VERSION ""

NS_ :

BS_:

BU_: Reserve2 SS_WaterTemperature4 SS_WaterTemperature3 SS_WaterTemperature2 SS_WaterTemperature1 SS_WaterPump2 SS_WaterPump1 SS_WaterFlow SS_SteeringAngle SS_RTDS SS_DFR SS_DFL SS_DBR SS_DBL VCU User Reserve1 Telemetry SS_BreakLight SmartSensor PedalIntegratedCircuit Distri Dashboard AclrGPS
VAL_TABLE_ AliveSignal 1 "ONLINE" 0 "OFFLINE" ;

BO_ 563 msg_VCU_cmd_PICoptions: 1 VCU
 SG_ sig_VCU_cmdPICverbose : 0|1@1- (1,0) [0|0] ""  PedalIntegratedCircuit

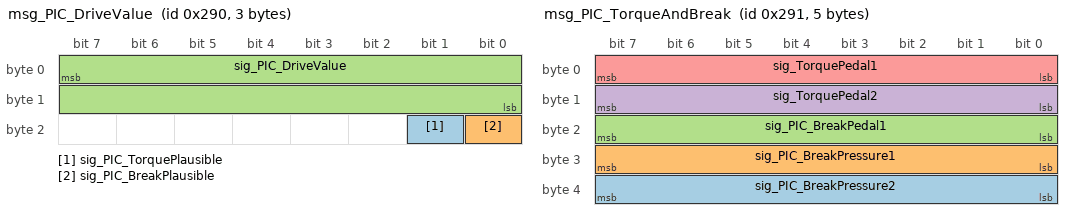
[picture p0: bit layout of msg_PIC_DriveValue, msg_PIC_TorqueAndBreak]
BO_ 656 msg_PIC_DriveValue: 3 PedalIntegratedCircuit
 SG_ sig_PIC_TorquePlausible : 17|1@0+ (1,0) [0|1] "" Vector__XXX
 SG_ sig_PIC_BreakPlausible : 16|1@0+ (1,0) [0|0] ""  VCU
 SG_ sig_PIC_DriveValue : 7|16@0- (0.0030518,0) [-100.0013824|99.9983306] ""  VCU

BO_ 863 msg_SS_WaterFlow1: 1 SS_WaterFlow
 SG_ sig_WaterFlow1 : 7|8@0+ (1,0) [0|255] ""  VCU

BO_ 561 msg_VCU_Alive: 1 VCU
 SG_ sig_VCU_Alive_Signal : 0|1@0+ (1,0) [0|0] ""  User

BO_ 657 msg_PIC_TorqueAndBreak: 5 PedalIntegratedCircuit
 SG_ sig_PIC_BreakPressure2 : 39|8@0+ (1,0) [0|255] ""  VCU
 SG_ sig_PIC_BreakPressure1 : 31|8@0+ (1,0) [0|255] ""  VCU
 SG_ sig_PIC_BreakPedal1 : 23|8@0+ (1,0) [0|255] ""  VCU
 SG_ sig_TorquePedal2 : 15|8@0+ (1,0) [0|255] ""  VCU
 SG_ sig_TorquePedal1 : 7|8@0+ (1,0) [0|255] ""  VCU

BO_ 800 msg_SS_CMD_BrakeLight: 1 VCU
 SG_ sig_BrakeLight_ON : 0|1@0+ (1,0) [0|0] ""  SS_BreakLight

BO_ 801 msg_SS_CMD_RTDS: 1 VCU
 SG_ sig_RTDS_ON : 0|1@0+ (1,0) [0|0] ""  SS_RTDS

BO_ 802 msg_SS_CMD_WaterPump1: 1 VCU
 SG_ sig_WaterPump1_ON : 0|1@0+ (1,0) [0|0] ""  SS_WaterPump1

BO_ 803 msg_SS_CMD_WaterPump2: 1 VCU
 SG_ sig_WaterPump2_ON : 0|1@0+ (1,0) [0|0] ""  SS_WaterPump2

BO_ 848 msg_SS_Deflection_FL: 2 SS_DFL
 SG_ sig_DeflectionFrontLeft : 7|16@0- (1,0) [-32768|32767] ""  VCU

BO_ 849 msg_SS_Deflection_FR: 2 SS_DFR
 SG_ sig_DeflectionFrontRight : 7|16@0- (1,0) [-32768|32767] ""  VCU

BO_ 850 msg_SS_Deflection_BL: 2 SS_DBL
 SG_ sig_DeflectionBackLeft : 7|16@0- (1,0) [-32768|32767] ""  VCU

BO_ 851 msg_SS_Deflection_BR: 2 SS_DBR
 SG_ sig_DeflectionBackRight : 7|16@0- (1,0) [-32768|32767] ""  VCU

BO_ 852 msg_SS_SteeringAngle: 2 SS_SteeringAngle
 SG_ sig_SteeringAngle : 0|16@1- (1,0) [-32768|32767] ""  VCU

BO_ 864 msg_SS_WaterTemp1: 1 SS_WaterTemperature1
 SG_ sig_TemperatureWater1 : 7|8@0+ (1,0) [0|255] ""  VCU

BO_ 865 msg_SS_WaterTemp2: 1 SS_WaterTemperature2
 SG_ sig_TemperatureWater2 : 7|8@0+ (1,0) [0|255] ""  VCU

BO_ 866 msg_SS_WaterTemp3: 1 SS_WaterTemperature3
 SG_ sig_TemperatureWater3 : 7|8@0+ (1,0) [0|255] ""  VCU

BO_ 867 msg_SS_WaterTemp4: 1 SS_WaterTemperature4
 SG_ sig_TemperatureWater4 : 7|8@0+ (1,0) [0|255] ""  VCU

BO_ 868 msg_SS_WaterPump1: 1 SS_WaterPump1
 SG_ sig_WaterPump1_State : 0|1@0+ (1,0) [0|0] ""  VCU

BO_ 869 msg_SS_WaterPump2: 1 SS_WaterPump2
 SG_ sig_WaterPump2_State : 0|1@0+ (1,0) [0|0] ""  VCU

CM_ BU_ SS_WaterTemperature4 "SmartSensor Water Temperature 4";
CM_ BU_ SS_WaterTemperature3 "SmartSensor Water Temperature 3";
CM_ BU_ SS_WaterTemperature2 "SmartSensor Water Temperature 2";
CM_ BU_ SS_WaterTemperature1 "SmartSensor Water Temperature 1";
CM_ BU_ SS_WaterPump2 "SmartSensor Water Pump 2";
CM_ BU_ SS_WaterPump1 "SmartSensor Water Pump 1";
CM_ BU_ SS_WaterFlow "SmartSensor Water Flow";
CM_ BU_ SS_SteeringAngle "SmartSensor steering angle";
CM_ BU_ SS_RTDS "SmartSensor ready to drive sound";
CM_ BU_ SS_DFR "SmartSensor Deflection Front Right";
CM_ BU_ SS_DFL "SmartSensor Deflection Front Left";
CM_ BU_ SS_DBR "Smart Sensor Deflection Back Right";
CM_ BU_ SS_DBL "SmartSensor Deflection Back Left";
CM_ BU_ User "extern developer eg. with CANoe";
CM_ BU_ SS_BreakLight "SmartSensor Brake Light";
CM_ BU_ PedalIntegratedCircuit "Pedalerie Platine (IC - integrated circuit)";
VAL_ 561 sig_VCU_Alive_Signal 1 "ONLINE" 0 "OFFLINE" ;
